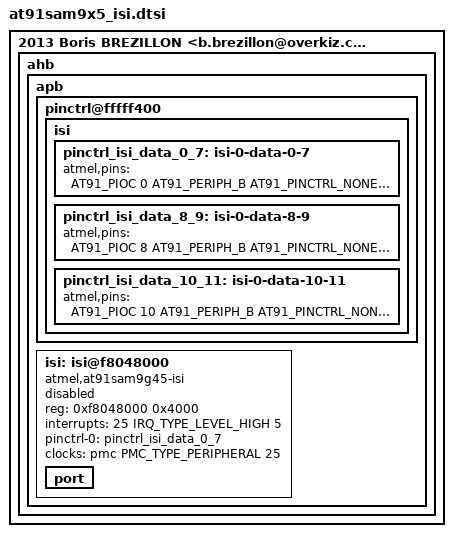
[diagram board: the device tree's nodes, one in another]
/* bench 6136.0.0 2f2715a574c9 */
/* bench 6136.0.1 44d177b27f95 */
/* bench 6136.0.2 559069999150 */
/*
/* bench 23410.1.0 9876468a916e */
/* bench 23410.1.1 00c501a1524f */
/* bench 23410.1.2 1223fe297a26 */
/* bench 23410.1.3 aa202b16e765 */
/* bench 23410.1.4 96169a323294 */
/* bench 23410.1.5 3d2547534ccd */
/* bench 23410.1.6 eb97e96ed089 */
 *
 * Copyright (C) 2013 Boris BREZILLON <b.brezillon@overkiz.com>
 */

#include <dt-bindings/pinctrl/at91.h>
/* bench 13000.2.0 6538bdacd7e0 */
/* bench 13000.2.1 3be3fb4bece1 */
/* bench 13000.2.2 f934d307b2ae */
/* bench 13000.2.3 0337baeb84ed */
/* bench 13000.2.4 7cc3abc37eaf */
/* bench 13000.2.5 8324dda55063 */
/* bench 13000.2.6 2fe47a6a0927 */
#include <dt-bindings/interrupt-controller/irq.h>

/ {
	ahb {
		apb {
			pinctrl@fffff400 {
				isi {
					pinctrl_isi_data_0_7: isi-0-data-0-7 {
						atmel,pins =
							<AT91_PIOC 0 AT91_PERIPH_B AT91_PINCTRL_NONE	/* ISI_D0, conflicts with LCDDAT0 */
							AT91_PIOC 1 AT91_PERIPH_B AT91_PINCTRL_NONE	/* ISI_D1, conflicts with LCDDAT1 */
							AT91_PIOC 2 AT91_PERIPH_B AT91_PINCTRL_NONE	/* ISI_D2, conflicts with LCDDAT2 */
/* bench 1276.0.0 598cc30ff11f */
/* bench 1276.0.1 a42a65e938de */
/* bench 1276.0.2 0900077b8146 */
/* bench 1276.0.3 d5f15e9e3c59 */
/* bench 1276.0.4 8f5ca7b71464 */
							AT91_PIOC 4 AT91_PERIPH_B AT91_PINCTRL_NONE	/* ISI_D4, conflicts with LCDDAT4 */
							AT91_PIOC 5 AT91_PERIPH_B AT91_PINCTRL_NONE	/* ISI_D5, conflicts with LCDDAT5 */
							AT91_PIOC 6 AT91_PERIPH_B AT91_PINCTRL_NONE	/* ISI_D6, conflicts with LCDDAT6 */
							AT91_PIOC 7 AT91_PERIPH_B AT91_PINCTRL_NONE	/* ISI_D7, conflicts with LCDDAT7 */
							AT91_PIOC 12 AT91_PERIPH_B AT91_PINCTRL_NONE	/* ISI_PCK, conflicts with LCDDAT12 */
							AT91_PIOC 14 AT91_PERIPH_B AT91_PINCTRL_NONE	/* ISI_HSYNC, conflicts with LCDDAT14 */
							AT91_PIOC 13 AT91_PERIPH_B AT91_PINCTRL_NONE>;	/* ISI_VSYNC, conflicts with LCDDAT13 */
					};

					pinctrl_isi_data_8_9: isi-0-data-8-9 {
						atmel,pins =
							<AT91_PIOC 8 AT91_PERIPH_B AT91_PINCTRL_NONE	/* ISI_D8, conflicts with LCDDAT8 */
							AT91_PIOC 9 AT91_PERIPH_B AT91_PINCTRL_NONE>;	/* ISI_D9, conflicts with LCDDAT9 */
					};

					pinctrl_isi_data_10_11: isi-0-data-10-11 {
						atmel,pins =
							<AT91_PIOC 10 AT91_PERIPH_B AT91_PINCTRL_NONE	/* ISI_D10, conflicts with LCDDAT10 */
							AT91_PIOC 11 AT91_PERIPH_B AT91_PINCTRL_NONE>;	/* ISI_D11, conflicts with LCDDAT11 */
					};
				};
			};

			isi: isi@f8048000 {
				compatible = "atmel,at91sam9g45-isi";
				reg = <0xf8048000 0x4000>;
				interrupts = <25 IRQ_TYPE_LEVEL_HIGH 5>;
				pinctrl-names = "default";
				pinctrl-0 = <&pinctrl_isi_data_0_7>;
				clocks = <&pmc PMC_TYPE_PERIPHERAL 25>;
				clock-names = "isi_clk";
				status = "disabled";
				port {
					#address-cells = <1>;
					#size-cells = <0>;
				};
			};
		};
	};
};
